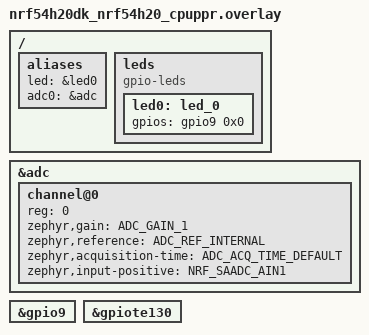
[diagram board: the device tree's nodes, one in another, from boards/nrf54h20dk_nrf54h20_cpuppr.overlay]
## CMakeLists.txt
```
#
# Copyright (c) 2023 Nordic Semiconductor
#
# SPDX-License-Identifier: LicenseRef-Nordic-5-Clause
#

cmake_minimum_required(VERSION 3.13.1)
find_package(Zephyr REQUIRED HINTS $ENV{ZEPHYR_BASE})
zephyr_include_directories(include)

project(adc)

target_sources(app PRIVATE ./../common/main.c)
target_sources(app PRIVATE src/driver_test.c)
```

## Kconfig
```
#
# Copyright (c) 20245 Nordic Semiconductor ASA
#
# SPDX-License-Identifier: LicenseRef-Nordic-5-Clause
#


choice LOCAL_DOMAIN_CLOCK_FREQUENCY_OPTION
	prompt "Local domain clock frequency"
	default LOCAL_DOMAIN_CLOCK_FREQUENCY_OPTION_320MHZ

config LOCAL_DOMAIN_CLOCK_FREQUENCY_OPTION_320MHZ
	bool "320MHz"

config LOCAL_DOMAIN_CLOCK_FREQUENCY_OPTION_128MHZ
	bool "128MHz"

config LOCAL_DOMAIN_CLOCK_FREQUENCY_OPTION_64MHZ
	bool "64MHz"

endchoice

config LOCAL_DOMAIN_CLOCK_FREQUENCY_MHZ
	int
	default 320 if LOCAL_DOMAIN_CLOCK_FREQUENCY_OPTION_320MHZ
	default 128 if LOCAL_DOMAIN_CLOCK_FREQUENCY_OPTION_128MHZ
	default 64 if LOCAL_DOMAIN_CLOCK_FREQUENCY_OPTION_64MHZ

source "Kconfig.zephyr"
```

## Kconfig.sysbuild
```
#
# Copyright (c) 2025 Nordic Semiconductor ASA
#
# SPDX-License-Identifier: LicenseRef-Nordic-5-Clause
#

choice NETCORE
	default NETCORE_REMOTE_SLEEP_FOREVER

config NETCORE_REMOTE_SLEEP_FOREVER
	bool "Remote sleep forever image"

endchoice

config NETCORE_IMAGE_NAME
	default "remote_sleep_forever" if NETCORE_REMOTE_SLEEP_FOREVER

config NETCORE_IMAGE_PATH
	default "$(ZEPHYR_NRF_MODULE_DIR)/tests/benchmarks/power_consumption/common/remote_sleep_forever" if NETCORE_REMOTE_SLEEP_FOREVER

config SUPPORT_NETCORE
	default y if (SOC_NRF54H20_CPUPPR || SOC_NRF54H20_CPUAPP)

config NETCORE_REMOTE_BOARD_TARGET_CPUCLUSTER
	default "cpurad" if (SOC_NRF54H20_CPUPPR || SOC_NRF54H20_CPUAPP)

source "share/sysbuild/Kconfig"
```

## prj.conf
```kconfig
CONFIG_ADC=y
CONFIG_GPIO=y

CONFIG_CONSOLE=n
CONFIG_UART_CONSOLE=n
CONFIG_SERIAL=n
CONFIG_BOOT_BANNER=n
CONFIG_NCS_BOOT_BANNER=n
```

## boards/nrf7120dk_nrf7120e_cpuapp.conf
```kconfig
CONFIG_PM=y
CONFIG_PM_DEVICE=y
CONFIG_PM_DEVICE_RUNTIME=y
CONFIG_POWEROFF=y
```

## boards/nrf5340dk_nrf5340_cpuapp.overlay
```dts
/ {
	aliases {
		led = &led0;
		/delete-property/ led1;
		adc0 = &adc;
	};
};

/delete-node/ &led1;

&adc {
	#address-cells = <1>;
	#size-cells = <0>;

	channel@0 {
		reg = <0>;
		zephyr,gain = "ADC_GAIN_1";
		zephyr,reference = "ADC_REF_INTERNAL";
		zephyr,acquisition-time = <ADC_ACQ_TIME_DEFAULT>;
		zephyr,input-positive = <NRF_SAADC_AIN1>;
	};
};

&vregmain {
	regulator-initial-mode = <NRF5X_REG_MODE_LDO>;
};
```

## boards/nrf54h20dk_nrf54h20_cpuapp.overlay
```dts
/ {
	aliases {
		led = &led0;
		/delete-property/ led1;
		adc0 = &adc;
	};
};

/delete-node/ &led1;

&adc {
	#address-cells = <1>;
	#size-cells = <0>;

	channel@0 {
		reg = <0>;
		zephyr,gain = "ADC_GAIN_1";
		zephyr,reference = "ADC_REF_INTERNAL";
		zephyr,acquisition-time = <ADC_ACQ_TIME_DEFAULT>;
		zephyr,input-positive = <NRF_SAADC_AIN1>;
	};
};
```

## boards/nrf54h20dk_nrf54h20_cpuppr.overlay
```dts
/ {
	aliases {
		led = &led0;
		adc0 = &adc;
	};

	leds {
		compatible = "gpio-leds";

		led0: led_0 {
			gpios = <&gpio9 0x0 0x0>;
		};
	};
};

&adc {
	#address-cells = <1>;
	#size-cells = <0>;
	status = "okay";

	channel@0 {
		reg = <0>;
		zephyr,gain = "ADC_GAIN_1";
		zephyr,reference = "ADC_REF_INTERNAL";
		zephyr,acquisition-time = <ADC_ACQ_TIME_DEFAULT>;
		zephyr,input-positive = <NRF_SAADC_AIN1>;
	};
};

&gpio9 {
	status = "okay";
};

&gpiote130 {
	status = "okay";
};
```

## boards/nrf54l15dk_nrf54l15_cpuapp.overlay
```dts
/ {
	aliases {
		led = &button3;
		adc0 = &adc;
	};
};

&adc {
	#address-cells = <1>;
	#size-cells = <0>;

	channel@0 {
		reg = <0>;
		zephyr,gain = "ADC_GAIN_1";
		zephyr,reference = "ADC_REF_INTERNAL";
		zephyr,acquisition-time = <ADC_ACQ_TIME_DEFAULT>;
		zephyr,input-positive = <NRF_SAADC_AIN1>;
	};
};
```

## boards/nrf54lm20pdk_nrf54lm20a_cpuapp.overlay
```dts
/ {
	aliases {
		led = &led0;
		/delete-property/ led1;
		adc0 = &adc;
	};
};

/delete-node/ &led1;

&adc {
	#address-cells = <1>;
	#size-cells = <0>;
	status = "okay";

	channel@0 {
		reg = <0>;
		zephyr,gain = "ADC_GAIN_1";
		zephyr,reference = "ADC_REF_INTERNAL";
		zephyr,acquisition-time = <ADC_ACQ_TIME(ADC_ACQ_TIME_MICROSECONDS, 10)>;
		zephyr,input-positive = <NRF_SAADC_AIN1>;  /* P1.31 */
		zephyr,resolution = <10>;
	};
};
```

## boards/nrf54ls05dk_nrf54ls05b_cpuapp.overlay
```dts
/ {
	aliases {
		led = &led0;
		/delete-property/ led1;
		adc0 = &adc;
	};
};

/delete-node/ &led1;

&adc {
	#address-cells = <1>;
	#size-cells = <0>;
	status = "okay";

	channel@0 {
		reg = <0>;
		zephyr,gain = "ADC_GAIN_1";
		zephyr,reference = "ADC_REF_INTERNAL";
		zephyr,acquisition-time = <ADC_ACQ_TIME_DEFAULT>;
		zephyr,input-positive = <NRF_SAADC_AIN3>;
		zephyr,resolution = <14>;
	};
};
```

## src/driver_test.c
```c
/*
 * Copyright (c) 2024 Nordic Semiconductor ASA
 *
 * SPDX-License-Identifier: LicenseRef-Nordic-5-Clause
 */

#include <zephyr/drivers/adc.h>
#include <zephyr/kernel.h>
#define ADC_NODE DT_ALIAS(adc0)
static const struct device *adc = DEVICE_DT_GET(ADC_NODE);

/* Get the number of channels defined on the DTS. */
static const struct adc_channel_cfg channel_cfgs[] = {
DT_FOREACH_CHILD_SEP(ADC_NODE, ADC_CHANNEL_CFG_DT, (,))};

static bool suspend_req;

bool self_suspend_req(void)
{
	suspend_req = true;
	return true;
}

void thread_definition(void)
{
	uint16_t channel_reading[5];
	int ret;

	/* Options for the sequence sampling. */
	const struct adc_sequence_options options = {
		.extra_samplings = 1,
		.interval_us = 0,
	};

	struct adc_sequence sequence = {
		.buffer = channel_reading,
		/* buffer size in bytes, not number of samples */
		.buffer_size = sizeof(channel_reading),
		.resolution = 12,
		.options = &options,
		.channels = 1,
	};

	ret = adc_channel_setup(adc, &channel_cfgs[0]);
	if (ret < 0) {
		printk("Issue with setting up channel, terminating thread.");
		return;
	}
	while (1) {
		if (suspend_req) {
			suspend_req = false;
			k_thread_suspend(k_current_get());
		}

#if defined(CONFIG_ADC_ASYNC)
		ret = adc_read_async(adc, &sequence, NULL);
#else
		ret = adc_read(adc, &sequence);
#endif

		if (ret < 0) {
			printk("Issue wih reading voltage, terminating thread.");
			return;
		}
	};
};
```
